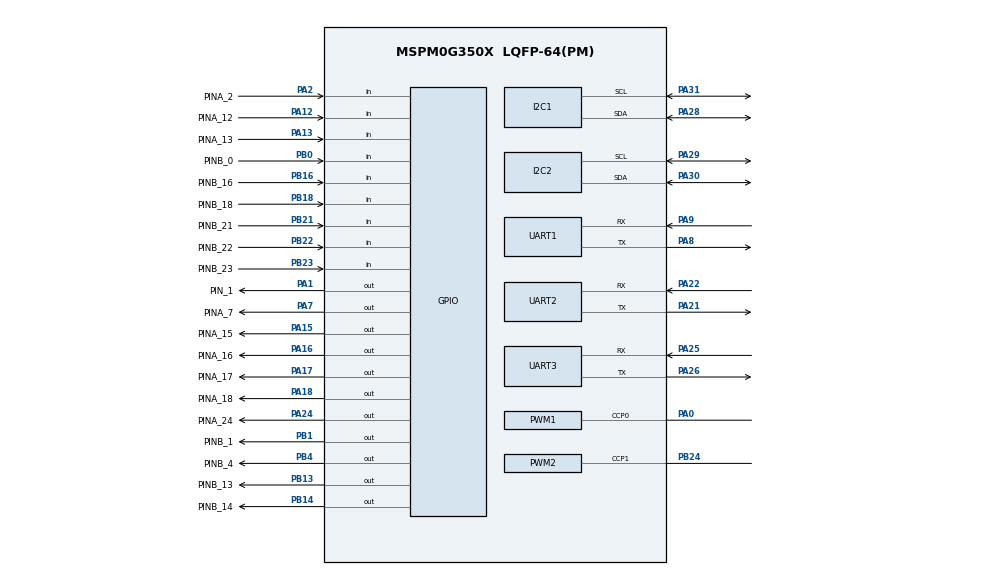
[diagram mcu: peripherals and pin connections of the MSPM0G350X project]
/**
 * @cliArgs --device "MSPM0G350X" --part "Default" --package "LQFP-64(PM)" --product "mspm0_sdk@2.11.00.07"
 * @versions {"tool":"1.26.2+4477"}
 */

/**
 * Import the modules used in this configuration.
 */
const Board   = scripting.addModule("/ti/driverlib/Board");
const GPIO    = scripting.addModule("/ti/driverlib/GPIO", {}, false);
const GPIO1   = GPIO.addInstance();
const GPIO2   = GPIO.addInstance();
const GPIO3   = GPIO.addInstance();
const GPIO4   = GPIO.addInstance();
const GPIO5   = GPIO.addInstance();
const GPIO6   = GPIO.addInstance();
const GPIO7   = GPIO.addInstance();
const GPIO8   = GPIO.addInstance();
const GPIO9   = GPIO.addInstance();
const I2C     = scripting.addModule("/ti/driverlib/I2C", {}, false);
const I2C1    = I2C.addInstance();
const I2C2    = I2C.addInstance();
const PWM     = scripting.addModule("/ti/driverlib/PWM", {}, false);
const PWM1    = PWM.addInstance();
const PWM2    = PWM.addInstance();
const SYSCTL  = scripting.addModule("/ti/driverlib/SYSCTL");
const SYSTICK = scripting.addModule("/ti/driverlib/SYSTICK");
const TIMER   = scripting.addModule("/ti/driverlib/TIMER", {}, false);
const TIMER1  = TIMER.addInstance();
const UART    = scripting.addModule("/ti/driverlib/UART", {}, false);
const UART1   = UART.addInstance();
const UART2   = UART.addInstance();
const UART3   = UART.addInstance();

/**
 * Write custom configuration values to the imported modules.
 */
Board.configureUnused = true;

GPIO1.$name                         = "GPIO_Drive_A";
GPIO1.port                          = "PORTA";
GPIO1.associatedPins.create(2);
GPIO1.associatedPins[0].$name       = "PINA_17";
GPIO1.associatedPins[0].pin.$assign = "PA17";
GPIO1.associatedPins[1].$name       = "PINA_16";
GPIO1.associatedPins[1].pin.$assign = "PA16";

GPIO2.$name                         = "GPIO_Drive_B";
GPIO2.port                          = "PORTB";
GPIO2.associatedPins.create(2);
GPIO2.associatedPins[0].$name       = "PINB_4";
GPIO2.associatedPins[0].pin.$assign = "PB4";
GPIO2.associatedPins[1].$name       = "PINB_1";
GPIO2.associatedPins[1].pin.$assign = "PB1";

GPIO3.$name                              = "GPIO_trace";
GPIO3.associatedPins.create(4);
GPIO3.associatedPins[0].assignedPort     = "PORTA";
GPIO3.associatedPins[0].$name            = "PINA_18";
GPIO3.associatedPins[0].pin.$assign      = "PA18";
GPIO3.associatedPins[1].assignedPort     = "PORTA";
GPIO3.associatedPins[1].$name            = "PINA_24";
GPIO3.associatedPins[1].pin.$assign      = "PA24";
GPIO3.associatedPins[2].assignedPort     = "PORTA";
GPIO3.associatedPins[2].$name            = "PINA_15";
GPIO3.associatedPins[2].pin.$assign      = "PA15";
GPIO3.associatedPins[3].assignedPort     = "PORTB";
GPIO3.associatedPins[3].$name            = "PINB_18";
GPIO3.associatedPins[3].direction        = "INPUT";
GPIO3.associatedPins[3].internalResistor = "PULL_DOWN";
GPIO3.associatedPins[3].pin.$assign      = "PB18";

GPIO4.$name                          = "GPIO_Buzzer";
GPIO4.port                           = "PORTB";
GPIO4.associatedPins[0].$name        = "PINB_13";
GPIO4.associatedPins[0].initialValue = "SET";
GPIO4.associatedPins[0].pin.$assign  = "PB13";

GPIO5.$name                                 = "GPIO_KEY";
GPIO5.associatedPins.create(3);
GPIO5.associatedPins[0].$name               = "PINB_0";
GPIO5.associatedPins[0].assignedPort        = "PORTB";
GPIO5.associatedPins[0].direction           = "INPUT";
GPIO5.associatedPins[0].internalResistor    = "PULL_UP";
GPIO5.associatedPins[0].pin.$assign         = "PB0";
GPIO5.associatedPins[1].$name               = "PINB_16";
GPIO5.associatedPins[1].assignedPort        = "PORTB";
GPIO5.associatedPins[1].direction           = "INPUT";
GPIO5.associatedPins[1].internalResistor    = "PULL_UP";
GPIO5.associatedPins[1].pin.$assign         = "PB16";
GPIO5.associatedPins[2].$name               = "PINA_2";
GPIO5.associatedPins[2].assignedPort        = "PORTA";
GPIO5.associatedPins[2].direction           = "INPUT";
GPIO5.associatedPins[2].internalResistor    = "PULL_UP";
GPIO5.associatedPins[2].pin.$assign         = "PA2";

GPIO6.$name                          = "GPIO_H";
GPIO6.associatedPins.create(4);
GPIO6.associatedPins[0].$name        = "PINB_22";
GPIO6.associatedPins[0].assignedPort = "PORTB";
GPIO6.associatedPins[0].direction    = "INPUT";
GPIO6.associatedPins[0].interruptEn  = true;
GPIO6.associatedPins[0].polarity     = "RISE_FALL";
GPIO6.associatedPins[0].pin.$assign  = "PB22";
GPIO6.associatedPins[1].$name        = "PINB_23";
GPIO6.associatedPins[1].direction    = "INPUT";
GPIO6.associatedPins[1].pin.$assign  = "PB23";
GPIO6.associatedPins[2].$name        = "PINA_12";
GPIO6.associatedPins[2].assignedPort = "PORTA";
GPIO6.associatedPins[2].direction    = "INPUT";
GPIO6.associatedPins[2].interruptEn  = true;
GPIO6.associatedPins[2].polarity     = "RISE_FALL";
GPIO6.associatedPins[2].pin.$assign  = "PA12";
GPIO6.associatedPins[3].$name        = "PINA_13";
GPIO6.associatedPins[3].assignedPort = "PORTA";
GPIO6.associatedPins[3].direction    = "INPUT";
GPIO6.associatedPins[3].pin.$assign  = "PA13";

GPIO7.$name                         = "GPIO_Echo";
GPIO7.associatedPins.create(2);
GPIO7.associatedPins[0].$name       = "PINA_7";
GPIO7.associatedPins[0].pin.$assign = "PA7";
GPIO7.associatedPins[1].$name       = "PINB_14";
GPIO7.associatedPins[1].pin.$assign = "PB14";

GPIO8.$name                          = "GPIO_GRP_0";
GPIO8.port                           = "PORTA";
GPIO8.associatedPins[0].$name        = "PIN_1";
GPIO8.associatedPins[0].initialValue = "SET";
GPIO8.associatedPins[0].pin.$assign  = "PA1";

GPIO9.$name                                = "GPIO_BUTTON";
GPIO9.port                                 = "PORTB";
GPIO9.associatedPins[0].$name              = "PINB_21";
GPIO9.associatedPins[0].direction          = "INPUT";
GPIO9.associatedPins[0].internalResistor   = "PULL_UP";
GPIO9.associatedPins[0].pin.$assign        = "PB21";

I2C1.$name                             = "I2C_MPU6050";
I2C1.basicEnableController             = true;
I2C1.peripheral.$assign                = "I2C0";
I2C1.peripheral.sdaPin.$assign         = "PA28";
I2C1.peripheral.sclPin.$assign         = "PA31";
I2C1.sdaPinConfig.hideOutputInversion  = scripting.forceWrite(false);
I2C1.sdaPinConfig.onlyInternalResistor = scripting.forceWrite(false);
I2C1.sdaPinConfig.passedPeripheralType = scripting.forceWrite("Digital");
I2C1.sdaPinConfig.$name                = "ti_driverlib_gpio_GPIOPinGeneric1";
I2C1.sdaPinConfig.enableConfig         = true;
I2C1.sclPinConfig.hideOutputInversion  = scripting.forceWrite(false);
I2C1.sclPinConfig.onlyInternalResistor = scripting.forceWrite(false);
I2C1.sclPinConfig.passedPeripheralType = scripting.forceWrite("Digital");
I2C1.sclPinConfig.$name                = "ti_driverlib_gpio_GPIOPinGeneric3";
I2C1.sclPinConfig.enableConfig         = true;

I2C2.$name                             = "I2C_OLED";
I2C2.basicEnableController             = true;
I2C2.peripheral.$assign                = "I2C1";
I2C2.peripheral.sdaPin.$assign         = "PA30";
I2C2.peripheral.sclPin.$assign         = "PA29";
I2C2.sdaPinConfig.hideOutputInversion  = scripting.forceWrite(false);
I2C2.sdaPinConfig.onlyInternalResistor = scripting.forceWrite(false);
I2C2.sdaPinConfig.passedPeripheralType = scripting.forceWrite("Digital");
I2C2.sdaPinConfig.$name                = "ti_driverlib_gpio_GPIOPinGeneric10";
I2C2.sclPinConfig.hideOutputInversion  = scripting.forceWrite(false);
I2C2.sclPinConfig.onlyInternalResistor = scripting.forceWrite(false);
I2C2.sclPinConfig.passedPeripheralType = scripting.forceWrite("Digital");
I2C2.sclPinConfig.$name                = "ti_driverlib_gpio_GPIOPinGeneric11";

PWM1.$name                              = "PWM_A";
PWM1.ccIndex                            = [0];
PWM1.timerCount                         = 3200;
PWM1.timerStartTimer                    = true;
PWM1.pwmMode                            = "EDGE_ALIGN_UP";
PWM1.PWM_CHANNEL_0.$name                = "ti_driverlib_pwm_PWMTimerCC0";
PWM1.PWM_CHANNEL_0.dutyCycle            = 50;
PWM1.ccp0PinConfig.direction            = scripting.forceWrite("OUTPUT");
PWM1.ccp0PinConfig.hideOutputInversion  = scripting.forceWrite(false);
PWM1.ccp0PinConfig.onlyInternalResistor = scripting.forceWrite(false);
PWM1.ccp0PinConfig.passedPeripheralType = scripting.forceWrite("Digital");
PWM1.ccp0PinConfig.$name                = "ti_driverlib_gpio_GPIOPinGeneric0";
PWM1.peripheral.$assign                 = "TIMA0";
PWM1.peripheral.ccp0Pin.$assign         = "PA0";

PWM2.$name                              = "PWM_B";
PWM2.timerCount                         = 3200;
PWM2.ccIndex                            = [1];
PWM2.timerStartTimer                    = true;
PWM2.pwmMode                            = "EDGE_ALIGN_UP";
PWM2.ccp1PinConfig.direction            = scripting.forceWrite("OUTPUT");
PWM2.ccp1PinConfig.hideOutputInversion  = scripting.forceWrite(false);
PWM2.ccp1PinConfig.onlyInternalResistor = scripting.forceWrite(false);
PWM2.ccp1PinConfig.passedPeripheralType = scripting.forceWrite("Digital");
PWM2.ccp1PinConfig.$name                = "ti_driverlib_gpio_GPIOPinGeneric2";
PWM2.peripheral.$assign                 = "TIMG12";
PWM2.peripheral.ccp1Pin.$assign         = "PB24";
PWM2.PWM_CHANNEL_1.$name                = "ti_driverlib_pwm_PWMTimerCC1";
PWM2.PWM_CHANNEL_1.ccValue              = 1600;
PWM2.PWM_CHANNEL_1.dutyCycle            = 50;

SYSCTL.forceDefaultClkConfig = true;
SYSCTL.clockTreeEn           = true;

SYSTICK.periodEnable  = true;
SYSTICK.period        = 32;
SYSTICK.systickEnable = true;

TIMER1.$name              = "TIMER_0";
TIMER1.timerClkPrescale   = 256;
TIMER1.timerMode          = "PERIODIC_UP";
TIMER1.timerStartTimer    = true;
TIMER1.interrupts         = ["ZERO"];
TIMER1.timerPeriod        = "1 ms";
TIMER1.peripheral.$assign = "TIMG0";

UART1.$name                            = "UART_1";
UART1.peripheral.rxPin.$assign         = "PA9";
UART1.peripheral.txPin.$assign         = "PA8";
UART1.txPinConfig.direction            = scripting.forceWrite("OUTPUT");
UART1.txPinConfig.hideOutputInversion  = scripting.forceWrite(false);
UART1.txPinConfig.onlyInternalResistor = scripting.forceWrite(false);
UART1.txPinConfig.passedPeripheralType = scripting.forceWrite("Digital");
UART1.txPinConfig.$name                = "ti_driverlib_gpio_GPIOPinGeneric4";
UART1.rxPinConfig.hideOutputInversion  = scripting.forceWrite(false);
UART1.rxPinConfig.onlyInternalResistor = scripting.forceWrite(false);
UART1.rxPinConfig.passedPeripheralType = scripting.forceWrite("Digital");
UART1.rxPinConfig.$name                = "ti_driverlib_gpio_GPIOPinGeneric5";

UART2.$name                            = "UART_2";
UART2.peripheral.rxPin.$assign         = "PA22";
UART2.peripheral.txPin.$assign         = "PA21";
UART2.txPinConfig.direction            = scripting.forceWrite("OUTPUT");
UART2.txPinConfig.hideOutputInversion  = scripting.forceWrite(false);
UART2.txPinConfig.onlyInternalResistor = scripting.forceWrite(false);
UART2.txPinConfig.passedPeripheralType = scripting.forceWrite("Digital");
UART2.txPinConfig.$name                = "ti_driverlib_gpio_GPIOPinGeneric6";
UART2.rxPinConfig.hideOutputInversion  = scripting.forceWrite(false);
UART2.rxPinConfig.onlyInternalResistor = scripting.forceWrite(false);
UART2.rxPinConfig.passedPeripheralType = scripting.forceWrite("Digital");
UART2.rxPinConfig.$name                = "ti_driverlib_gpio_GPIOPinGeneric7";

UART3.$name                            = "UART_3";
UART3.peripheral.rxPin.$assign         = "PA25";
UART3.peripheral.txPin.$assign         = "PA26";
UART3.txPinConfig.direction            = scripting.forceWrite("OUTPUT");
UART3.txPinConfig.hideOutputInversion  = scripting.forceWrite(false);
UART3.txPinConfig.onlyInternalResistor = scripting.forceWrite(false);
UART3.txPinConfig.passedPeripheralType = scripting.forceWrite("Digital");
UART3.txPinConfig.$name                = "ti_driverlib_gpio_GPIOPinGeneric8";
UART3.rxPinConfig.hideOutputInversion  = scripting.forceWrite(false);
UART3.rxPinConfig.onlyInternalResistor = scripting.forceWrite(false);
UART3.rxPinConfig.passedPeripheralType = scripting.forceWrite("Digital");
UART3.rxPinConfig.$name                = "ti_driverlib_gpio_GPIOPinGeneric9";

/**
 * Pinmux solution for unlocked pins/peripherals. This ensures that minor changes to the automatic solver in a future
 * version of the tool will not impact the pinmux you originally saw.  These lines can be completely deleted in order to
 * re-solve from scratch.
 */
Board.peripheral.$suggestSolution          = "DEBUGSS";
Board.peripheral.swclkPin.$suggestSolution = "PA20";
Board.peripheral.swdioPin.$suggestSolution = "PA19";
UART1.peripheral.$suggestSolution          = "UART1";
UART2.peripheral.$suggestSolution          = "UART2";
UART3.peripheral.$suggestSolution          = "UART3";
